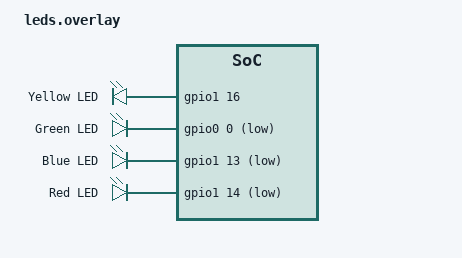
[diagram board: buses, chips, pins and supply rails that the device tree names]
/*
 * Arduino Nano ESP32: on-board LEDs.
 *
 * The esp32s3_devkitc_procpu.dts (found from -b esp32s3_devkitc/esp32s3/procpu)  has no LEDs, 
 * so samples such as blinky find no "led0". This overlay
 * adds the Nano's LEDs (schematic ABX00083) and the standard aliases led0-led3.
 *
 * Zephyr GPIO controllers: gpio0 = GPIO 0-31, gpio1 = GPIO 32-48 (pin = GPIO - 32).
 *
 * - Yellow LED ("SCK LED", D13) on GPIO48, driven through an N-channel MOSFET:
 *   gate high = LED on, so it is active high.
 * - RGB LED with common anode to 3V3: a pin driven low turns its colour on, so active low.
 *   The colour of each pin was found by testing (the schematic does not say).
 *
 * Note: GPIO0 and GPIO46 are boot strapping pins (GPIO0 low at reset = download mode).
 */

#include <zephyr/dt-bindings/gpio/gpio.h>

/ {
	aliases {
		led0 = &yellow_led;
		led1 = &green_led;
		led2 = &blue_led;
		led3 = &red_led;
	};

	leds {
		compatible = "gpio-leds";

		yellow_led: led_0 {
			gpios = <&gpio1 16 GPIO_ACTIVE_HIGH>; /* GPIO48 */
			label = "Yellow LED";
		};

		green_led: led_1 {
			gpios = <&gpio0 0 GPIO_ACTIVE_LOW>; /* GPIO0 */
			label = "Green LED";
		};

		blue_led: led_2 {
			gpios = <&gpio1 13 GPIO_ACTIVE_LOW>; /* GPIO45 */
			label = "Blue LED";
		};

		red_led: led_3 {
			gpios = <&gpio1 14 GPIO_ACTIVE_LOW>; /* GPIO46 */
			label = "Red LED";
		};
	};
};
